# STM32G534 register map
File version: 2.0.0
CPU: CM33 r0p4, little endian, MPU, FPU, 4 interrupt priority bits
Registers are 32-bit, read-write, reset 0x0 unless marked. A register's access mark holds for its fields unless they carry their own. Offsets are from the block's base; [hi:lo] are bit positions.

## ADCC12 — ADCC address block description
Base 0x42020300
Same registers: ADCC12_S 0x52020300
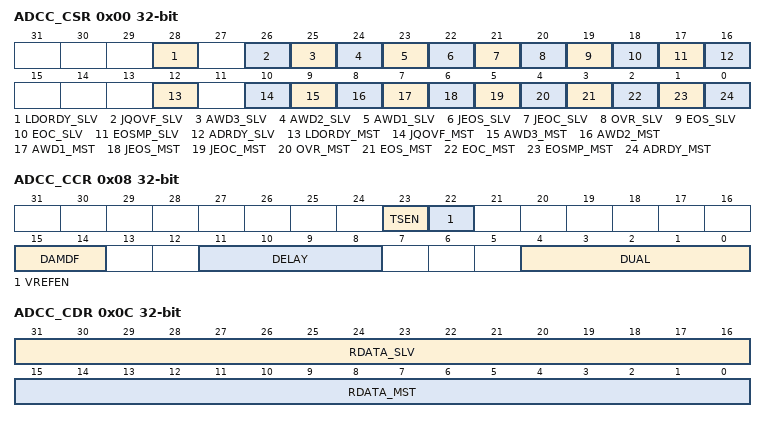
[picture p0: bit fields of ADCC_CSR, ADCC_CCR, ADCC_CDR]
0x00 ADCC_CSR ro — ADC common status register
  [28] LDORDY_SLV — ADC internal voltage regulator flag of the slave ADC
  [26] JQOVF_SLV — Injected context queue overflow flag of the slave ADC
  [25] AWD3_SLV — Analog watchdog 3 flag of the slave ADC
  [24] AWD2_SLV — Analog watchdog 2 flag of the slave ADC
  [23] AWD1_SLV — Analog watchdog 1 flag of the slave ADC
  [22] JEOS_SLV — End of injected sequence flag of the slave ADC
  [21] JEOC_SLV — End of injected conversion flag of the slave ADC
  [20] OVR_SLV — Overrun flag of the slave ADC
  [19] EOS_SLV — End of regular sequence flag of the slave ADC.
  [18] EOC_SLV — End of regular conversion of the slave ADC
  [17] EOSMP_SLV — End of sampling phase flag of the slave ADC
  [16] ADRDY_SLV — Slave ADC ready
  [12] LDORDY_MST — ADC internal voltage regulator flag of the master ADC
  [10] JQOVF_MST — Injected context queue overflow flag of the master ADC
  [9] AWD3_MST — Analog watchdog 3 flag of the master ADC
  [8] AWD2_MST — Analog watchdog 2 flag of the master ADC
  [7] AWD1_MST — Analog watchdog 1 flag of the master ADC
  [6] JEOS_MST — End of injected sequence flag of the master ADC
  [5] JEOC_MST — End of injected conversion flag of the master ADC
  [4] OVR_MST — Overrun flag of the master ADC
  [3] EOS_MST — End of regular sequence flag of the master ADC
  [2] EOC_MST — End of regular conversion of the master ADC
  [1] EOSMP_MST — End of Sampling phase flag of the master ADC
  [0] ADRDY_MST — Master ADC ready
0x08 ADCC_CCR — ADC common control register
  [23] TSEN — Temperature sensor voltage enable
    0=Temperature sensor channel disabled; 1=Temperature sensor channel enabled
  [22] VREFEN — Vless thansub>REFINTless than/sub> enable
    0=Vless thansub>REFINTless than/sub> channel disabled; 1=Vless thansub>REFINTless than/sub> channel enabled
  [15:14] DAMDF — Dual ADC mode data format
    0=Dual ADC mode without data packing (ADCC_CDR and ADCC_CDR2 registers not used); 2=Data formatting mode for any data width (ADCC_CDR data register is used when the data width is less than 16 bits, otherwise ADCC_CDR2 register is used); 3=Data formatting mode for data width lower that 8 bits (ADCC_CDR data register is used)
  [11:8] DELAY — Delay between two sampling phases
  [4:0] DUAL — Dual ADC mode selection
    0=Independent mode; 1=Combined regular simultaneous + Injected simultaneous mode; 2=Combined regular simultaneous + Alternate trigger mode; 3=Combined interleaved mode + Injected simultaneous mode; 5=Injected simultaneous mode only; 6=Regular simultaneous mode only; 7=Interleaved mode only; 9=Alternate trigger mode only
0x0C ADCC_CDR ro — ADC common regular data register for dual mode
  [31:16] RDATA_SLV — Regular data of the slave ADC
  [15:0] RDATA_MST — Regular data of the master ADC.
0x10 ADCC_CDR2 ro — ADC common regular data register for dual mode
  [31:0] RDATA_ALT — Regular data of the master/slave alternated ADCs.

## CORDIC1 — CORDIC register block
Base 0x40023800
Same registers: CORDIC1_S 0x50023800
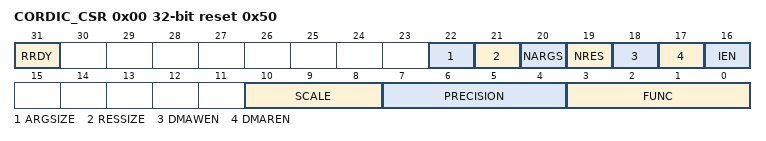
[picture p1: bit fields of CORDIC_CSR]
0x00 CORDIC_CSR reset 0x50 — CORDIC control/status register
  [31] RRDY ro — Result ready flag
    0=No new data in output register; 1=CORDIC_RDATA register contains new data
  [22] ARGSIZE — Width of input data
    0=32-bit; 1=16-bit
  [21] RESSIZE — Width of output data
    0=32-bit; 1=16-bit
  [20] NARGS — Number of arguments expected by the CORDIC_WDATA register
    0=Only one 32-bit write (or two 16-bit values if ARGSIZE = 1) is needed for the next calculation; 1=Two 32-bit values must be written to the CORDIC_WDATA register to trigger the next calculation
  [19] NRES — Number of results in the CORDIC_RDATA register
    0=Only one 32-bit value (or two 16-bit values if RESSIZE = 1) is transferred to the CORDIC_RDATA register on completion of the next calculation; 1=Two 32-bit values are transferred to the CORDIC_RDATA register on completion of the next calculation
  [18] DMAWEN — Enable DMA write channel
    0=Disabled; 1=Enabled
  [17] DMAREN — Enable DMA read channel
    0=Disabled; 1=Enabled
  [16] IEN — Enable interrupt.
    0=Disabled; 1=Enabled
  [10:8] SCALE — Scaling factor
  [7:4] PRECISION — Precision required (number of iterations)
  [3:0] FUNC — Function
    0=Cosine; 1=Sine
0x04 CORDIC_WDATA wo reset not defined — CORDIC argument register
  [31:0] ARG — Function input arguments
0x08 CORDIC_RDATA ro — CORDIC result register
  [31:0] RES — Function result

## Notices in the file
Copyright (c) 2026 STMicroelectronics.
SPDX-License-Identifier: Apache-2.0
Licensed under the Apache License, Version 2.0 (the "License");
you may not use this file except in compliance with the License.
You may obtain a copy of the License at
http://www.apache.org/licenses/LICENSE-2.0
Unless required by applicable law or agreed to in writing, software
distributed under the License is distributed on an "AS IS" BASIS,
WITHOUT WARRANTIES OR CONDITIONS OF ANY KIND, either express or implied.
See the License for the specific language governing permissions and
limitations under the License.
